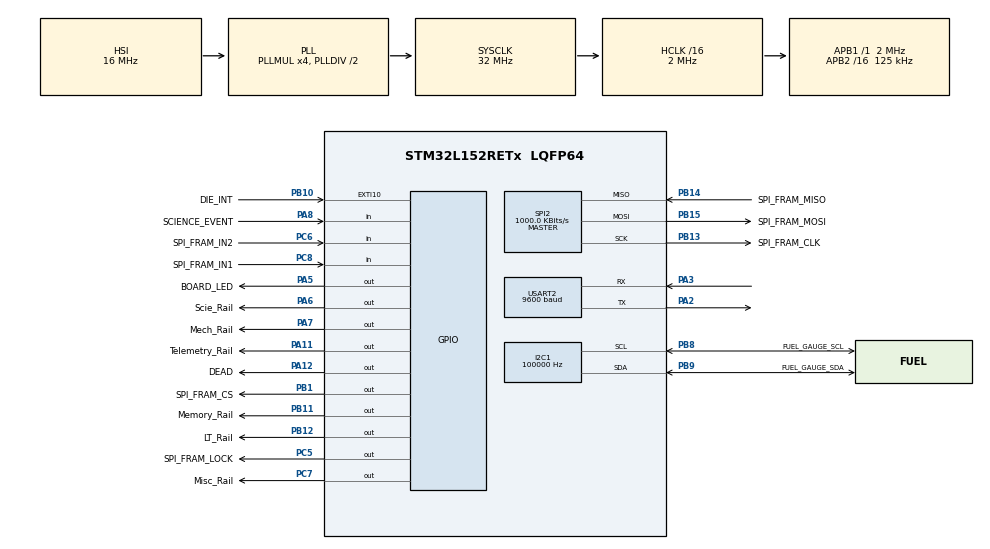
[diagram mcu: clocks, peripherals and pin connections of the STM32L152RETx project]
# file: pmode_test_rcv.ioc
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I2C1.ClockSpeed=100000
Mcu.Family=STM32L1
Mcu.Name=STM32L152RETx
Mcu.Package=LQFP64
NVIC.EXTI15_10_IRQn=true\:0\:0\:false\:false\:true\:true\:true
NVIC.PriorityGroup=NVIC_PRIORITYGROUP_4
NVIC.TIM10_IRQn=true\:0\:0\:false\:false\:true\:true\:true
PA11.GPIO_Label=Telemetry_Rail
PA11.Signal=GPIO_Output
PA12.GPIO_Label=DEAD
PA12.Signal=GPIO_Output
PA2.Mode=Asynchronous
PA2.Signal=USART2_TX
PA3.Mode=Asynchronous
PA3.Signal=USART2_RX
PA5.GPIO_Label=BOARD_LED
PA5.Signal=GPIO_Output
PA6.GPIO_Label=Scie_Rail
PA6.Signal=GPIO_Output
PA7.GPIO_Label=Mech_Rail
PA7.Signal=GPIO_Output
PA8.GPIO_Label=SCIENCE_EVENT
PA8.Signal=GPIO_Input
PB1.GPIO_Label=SPI_FRAM_CS
PB1.Signal=GPIO_Output
PB10.GPIO_Label=DIE_INT
PB10.Signal=GPXTI10
PB11.GPIO_Label=Memory_Rail
PB11.Signal=GPIO_Output
PB12.GPIO_Label=LT_Rail
PB12.Signal=GPIO_Output
PB13.GPIO_Label=SPI_FRAM_CLK
PB13.Mode=Full_Duplex_Master
PB13.Signal=SPI2_SCK
PB14.GPIO_Label=SPI_FRAM_MISO
PB14.Mode=Full_Duplex_Master
PB14.Signal=SPI2_MISO
PB15.GPIO_Label=SPI_FRAM_MOSI
PB15.Mode=Full_Duplex_Master
PB15.Signal=SPI2_MOSI
PB8.GPIO_Label=FUEL_GAUGE_SCL
PB8.Mode=I2C
PB8.Signal=I2C1_SCL
PB9.GPIO_Label=FUEL_GAUGE_SDA
PB9.Mode=I2C
PB9.Signal=I2C1_SDA
PC5.GPIO_Label=SPI_FRAM_LOCK
PC5.Signal=GPIO_Output
PC6.GPIO_Label=SPI_FRAM_IN2
PC6.Signal=GPIO_Input
PC7.GPIO_Label=Misc_Rail
PC7.Signal=GPIO_Output
PC8.GPIO_Label=SPI_FRAM_IN1
PC8.Signal=GPIO_Input
ProjectManager.HeapSize=0x200
ProjectManager.StackSize=0x400
ProjectManager.TargetToolchain=MDK-ARM V5
RCC.48MHZClocksFreq_Value=32000000
RCC.AHBCLKDivider=RCC_SYSCLK_DIV16
RCC.AHBFreq_Value=2000000
RCC.APB1Freq_Value=2000000
RCC.APB1TimFreq_Value=2000000
RCC.APB2CLKDivider=RCC_HCLK_DIV16
RCC.APB2Freq_Value=125000
RCC.APB2TimFreq_Value=250000
RCC.HCLKFreq_Value=2000000
RCC.HSE_VALUE=24000000
RCC.HSI_VALUE=16000000
RCC.LSE_VALUE=32768
RCC.MSIClockRange=RCC_MSIRANGE_6
RCC.MSI_VALUE=4194000
RCC.PLLMUL=RCC_PLL_MUL4
RCC.SYSCLKFreq_VALUE=32000000
RCC.SYSCLKSource=RCC_SYSCLKSOURCE_PLLCLK
RCC.VCOOutputFreq_Value=64000000
SPI2.BaudRatePrescaler=SPI_BAUDRATEPRESCALER_2
SPI2.CalculateBaudRate=1000.0 KBits/s
SPI2.Direction=SPI_DIRECTION_2LINES
SPI2.Mode=SPI_MODE_MASTER
SPI2.VirtualType=VM_MASTER
TIM10.ClockDivision=TIM_CLOCKDIVISION_DIV4
TIM10.Period=65535
USART2.BaudRate=9600
USART2.VirtualMode=VM_ASYNC
VP_TIM10_VS_ClockSourceINT.Mode=Internal
board=custom

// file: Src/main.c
/* USER CODE BEGIN Header */
/**
  ******************************************************************************
  * @file           : main.c
  * @brief          : Main program body
  ******************************************************************************
  ** This notice applies to any and all portions of this file
  * that are not between comment pairs USER CODE BEGIN and
  * USER CODE END. Other portions of this file, whether
  * inserted by the user or by software development tools
  * are owned by their respective copyright owners.
  *
  * COPYRIGHT(c) 2019 STMicroelectronics
  *
  * Redistribution and use in source and binary forms, with or without modification,
  * are permitted provided that the following conditions are met:
  *   1. Redistributions of source code must retain the above copyright notice,
  *      this list of conditions and the following disclaimer.
  *   2. Redistributions in binary form must reproduce the above copyright notice,
  *      this list of conditions and the following disclaimer in the documentation
  *      and/or other materials provided with the distribution.
  *   3. Neither the name of STMicroelectronics nor the names of its contributors
  *      may be used to endorse or promote products derived from this software
  *      without specific prior written permission.
  *
  * THIS SOFTWARE IS PROVIDED BY THE COPYRIGHT HOLDERS AND CONTRIBUTORS "AS IS"
  * AND ANY EXPRESS OR IMPLIED WARRANTIES, INCLUDING, BUT NOT LIMITED TO, THE
  * IMPLIED WARRANTIES OF MERCHANTABILITY AND FITNESS FOR A PARTICULAR PURPOSE ARE
  * DISCLAIMED. IN NO EVENT SHALL THE COPYRIGHT HOLDER OR CONTRIBUTORS BE LIABLE
  * FOR ANY DIRECT, INDIRECT, INCIDENTAL, SPECIAL, EXEMPLARY, OR CONSEQUENTIAL
  * DAMAGES (INCLUDING, BUT NOT LIMITED TO, PROCUREMENT OF SUBSTITUTE GOODS OR
  * SERVICES; LOSS OF USE, DATA, OR PROFITS; OR BUSINESS INTERRUPTION) HOWEVER
  * CAUSED AND ON ANY THEORY OF LIABILITY, WHETHER IN CONTRACT, STRICT LIABILITY,
  * OR TORT (INCLUDING NEGLIGENCE OR OTHERWISE) ARISING IN ANY WAY OUT OF THE USE
  * OF THIS SOFTWARE, EVEN IF ADVISED OF THE POSSIBILITY OF SUCH DAMAGE.
  *
  ******************************************************************************
  */
/* USER CODE END Header */

#include "main.h"

/* USER CODE BEGIN Includes */
#include "PowerModes.h"

/* USER CODE END Includes */

I2C_HandleTypeDef hi2c1;

SPI_HandleTypeDef hspi2;

TIM_HandleTypeDef htim10;

UART_HandleTypeDef huart2;

void SystemClock_Config(void);
static void MX_GPIO_Init(void);
static void MX_SPI2_Init(void);
static void MX_USART2_UART_Init(void);
static void MX_I2C1_Init(void);
static void MX_TIM10_Init(void);

int main(void)
{

  /* MCU Configuration--------------------------------------------------------*/

  /* Reset of all peripherals, Initializes the Flash interface and the Systick. */
  HAL_Init();

  /* Configure the system clock */
  SystemClock_Config();

  /* Initialize all configured peripherals */
  MX_GPIO_Init();
  MX_SPI2_Init();
  MX_USART2_UART_Init();
  MX_I2C1_Init();
  MX_TIM10_Init();
  /* USER CODE BEGIN 2 */
	Power_Modes_State_Machine_Init(&hi2c1, &hspi2, &huart2, &htim10);

  /* USER CODE END 2 */

  /* Infinite loop */
  /* USER CODE BEGIN WHILE */

  while (1)
  {
//		float battPercentage = Get_Voltage(&hi2c1, 0); // Currently returns a value in volts
//		snprintf(msg, 200, "\nBatt: %f \n\n", battPercentage);
//		HAL_UART_Transmit(&huart2, (uint8_t *)msg, 200, 100);
//		HAL_Delay(1000);
			Power_Modes_State_Machine_Run();

    /* USER CODE END WHILE */

  }
}

void SystemClock_Config(void)
{
  RCC_OscInitTypeDef RCC_OscInitStruct = {0};
  RCC_ClkInitTypeDef RCC_ClkInitStruct = {0};

  /** Configure the main internal regulator output voltage
  */
  __HAL_PWR_VOLTAGESCALING_CONFIG(PWR_REGULATOR_VOLTAGE_SCALE1);
  /** Initializes the CPU, AHB and APB busses clocks
  */
  RCC_OscInitStruct.OscillatorType = RCC_OSCILLATORTYPE_HSI;
  RCC_OscInitStruct.HSIState = RCC_HSI_ON;
  RCC_OscInitStruct.HSICalibrationValue = RCC_HSICALIBRATION_DEFAULT;
  RCC_OscInitStruct.PLL.PLLState = RCC_PLL_ON;
  RCC_OscInitStruct.PLL.PLLSource = RCC_PLLSOURCE_HSI;
  RCC_OscInitStruct.PLL.PLLMUL = RCC_PLL_MUL4;
  RCC_OscInitStruct.PLL.PLLDIV = RCC_PLL_DIV2;
  if (HAL_RCC_OscConfig(&RCC_OscInitStruct) != HAL_OK)
  {
    Error_Handler();
  }
  /** Initializes the CPU, AHB and APB busses clocks
  */
  RCC_ClkInitStruct.ClockType = RCC_CLOCKTYPE_HCLK|RCC_CLOCKTYPE_SYSCLK
                              |RCC_CLOCKTYPE_PCLK1|RCC_CLOCKTYPE_PCLK2;
  RCC_ClkInitStruct.SYSCLKSource = RCC_SYSCLKSOURCE_PLLCLK;
  RCC_ClkInitStruct.AHBCLKDivider = RCC_SYSCLK_DIV16;
  RCC_ClkInitStruct.APB1CLKDivider = RCC_HCLK_DIV1;
  RCC_ClkInitStruct.APB2CLKDivider = RCC_HCLK_DIV16;

  if (HAL_RCC_ClockConfig(&RCC_ClkInitStruct, FLASH_LATENCY_0) != HAL_OK)
  {
    Error_Handler();
  }
}

static void MX_I2C1_Init(void)
{

  hi2c1.Instance = I2C1;
  hi2c1.Init.ClockSpeed = 100000;
  hi2c1.Init.DutyCycle = I2C_DUTYCYCLE_2;
  hi2c1.Init.OwnAddress1 = 0;
  hi2c1.Init.AddressingMode = I2C_ADDRESSINGMODE_7BIT;
  hi2c1.Init.DualAddressMode = I2C_DUALADDRESS_DISABLE;
  hi2c1.Init.OwnAddress2 = 0;
  hi2c1.Init.GeneralCallMode = I2C_GENERALCALL_DISABLE;
  hi2c1.Init.NoStretchMode = I2C_NOSTRETCH_DISABLE;
  if (HAL_I2C_Init(&hi2c1) != HAL_OK)
  {
    Error_Handler();
  }

}

static void MX_SPI2_Init(void)
{

  /* SPI2 parameter configuration*/
  hspi2.Instance = SPI2;
  hspi2.Init.Mode = SPI_MODE_MASTER;
  hspi2.Init.Direction = SPI_DIRECTION_2LINES;
  hspi2.Init.DataSize = SPI_DATASIZE_8BIT;
  hspi2.Init.CLKPolarity = SPI_POLARITY_LOW;
  hspi2.Init.CLKPhase = SPI_PHASE_1EDGE;
  hspi2.Init.NSS = SPI_NSS_SOFT;
  hspi2.Init.BaudRatePrescaler = SPI_BAUDRATEPRESCALER_2;
  hspi2.Init.FirstBit = SPI_FIRSTBIT_MSB;
  hspi2.Init.TIMode = SPI_TIMODE_DISABLE;
  hspi2.Init.CRCCalculation = SPI_CRCCALCULATION_DISABLE;
  hspi2.Init.CRCPolynomial = 10;
  if (HAL_SPI_Init(&hspi2) != HAL_OK)
  {
    Error_Handler();
  }

}

static void MX_TIM10_Init(void)
{

  TIM_ClockConfigTypeDef sClockSourceConfig = {0};

  htim10.Instance = TIM10;
  htim10.Init.Prescaler = 0;
  htim10.Init.CounterMode = TIM_COUNTERMODE_UP;
  htim10.Init.Period = 65535;
  htim10.Init.ClockDivision = TIM_CLOCKDIVISION_DIV4;
  htim10.Init.AutoReloadPreload = TIM_AUTORELOAD_PRELOAD_DISABLE;
  if (HAL_TIM_Base_Init(&htim10) != HAL_OK)
  {
    Error_Handler();
  }
  sClockSourceConfig.ClockSource = TIM_CLOCKSOURCE_INTERNAL;
  if (HAL_TIM_ConfigClockSource(&htim10, &sClockSourceConfig) != HAL_OK)
  {
    Error_Handler();
  }

}

static void MX_USART2_UART_Init(void)
{

  huart2.Instance = USART2;
  huart2.Init.BaudRate = 9600;
  huart2.Init.WordLength = UART_WORDLENGTH_8B;
  huart2.Init.StopBits = UART_STOPBITS_1;
  huart2.Init.Parity = UART_PARITY_NONE;
  huart2.Init.Mode = UART_MODE_TX_RX;
  huart2.Init.HwFlowCtl = UART_HWCONTROL_NONE;
  huart2.Init.OverSampling = UART_OVERSAMPLING_16;
  if (HAL_UART_Init(&huart2) != HAL_OK)
  {
    Error_Handler();
  }

}

static void MX_GPIO_Init(void)
{
  GPIO_InitTypeDef GPIO_InitStruct = {0};

  /* GPIO Ports Clock Enable */
  __HAL_RCC_GPIOA_CLK_ENABLE();
  __HAL_RCC_GPIOC_CLK_ENABLE();
  __HAL_RCC_GPIOB_CLK_ENABLE();

  /*Configure GPIO pin Output Level */
  HAL_GPIO_WritePin(GPIOA, BOARD_LED_Pin|Scie_Rail_Pin|Mech_Rail_Pin|Telemetry_Rail_Pin
                          |DEAD_Pin, GPIO_PIN_RESET);

  /*Configure GPIO pin Output Level */
  HAL_GPIO_WritePin(GPIOC, SPI_FRAM_LOCK_Pin|Misc_Rail_Pin, GPIO_PIN_RESET);

  /*Configure GPIO pin Output Level */
  HAL_GPIO_WritePin(GPIOB, SPI_FRAM_CS_Pin|Memory_Rail_Pin|LT_Rail_Pin, GPIO_PIN_RESET);

  /*Configure GPIO pins : BOARD_LED_Pin Scie_Rail_Pin Mech_Rail_Pin Telemetry_Rail_Pin
                           DEAD_Pin */
  GPIO_InitStruct.Pin = BOARD_LED_Pin|Scie_Rail_Pin|Mech_Rail_Pin|Telemetry_Rail_Pin
                          |DEAD_Pin;
  GPIO_InitStruct.Mode = GPIO_MODE_OUTPUT_PP;
  GPIO_InitStruct.Pull = GPIO_NOPULL;
  GPIO_InitStruct.Speed = GPIO_SPEED_FREQ_LOW;
  HAL_GPIO_Init(GPIOA, &GPIO_InitStruct);

  /*Configure GPIO pins : SPI_FRAM_LOCK_Pin Misc_Rail_Pin */
  GPIO_InitStruct.Pin = SPI_FRAM_LOCK_Pin|Misc_Rail_Pin;
  GPIO_InitStruct.Mode = GPIO_MODE_OUTPUT_PP;
  GPIO_InitStruct.Pull = GPIO_NOPULL;
  GPIO_InitStruct.Speed = GPIO_SPEED_FREQ_LOW;
  HAL_GPIO_Init(GPIOC, &GPIO_InitStruct);

  /*Configure GPIO pins : SPI_FRAM_CS_Pin Memory_Rail_Pin LT_Rail_Pin */
  GPIO_InitStruct.Pin = SPI_FRAM_CS_Pin|Memory_Rail_Pin|LT_Rail_Pin;
  GPIO_InitStruct.Mode = GPIO_MODE_OUTPUT_PP;
  GPIO_InitStruct.Pull = GPIO_NOPULL;
  GPIO_InitStruct.Speed = GPIO_SPEED_FREQ_LOW;
  HAL_GPIO_Init(GPIOB, &GPIO_InitStruct);

  /*Configure GPIO pin : DIE_INT_Pin */
  GPIO_InitStruct.Pin = DIE_INT_Pin;
  GPIO_InitStruct.Mode = GPIO_MODE_IT_RISING;
  GPIO_InitStruct.Pull = GPIO_NOPULL;
  HAL_GPIO_Init(DIE_INT_GPIO_Port, &GPIO_InitStruct);

  /*Configure GPIO pins : SPI_FRAM_IN2_Pin SPI_FRAM_IN1_Pin */
  GPIO_InitStruct.Pin = SPI_FRAM_IN2_Pin|SPI_FRAM_IN1_Pin;
  GPIO_InitStruct.Mode = GPIO_MODE_INPUT;
  GPIO_InitStruct.Pull = GPIO_NOPULL;
  HAL_GPIO_Init(GPIOC, &GPIO_InitStruct);

  /*Configure GPIO pin : SCIENCE_EVENT_Pin */
  GPIO_InitStruct.Pin = SCIENCE_EVENT_Pin;
  GPIO_InitStruct.Mode = GPIO_MODE_INPUT;
  GPIO_InitStruct.Pull = GPIO_NOPULL;
  HAL_GPIO_Init(SCIENCE_EVENT_GPIO_Port, &GPIO_InitStruct);

  /* EXTI interrupt init*/
  HAL_NVIC_SetPriority(EXTI15_10_IRQn, 0, 0);
  HAL_NVIC_EnableIRQ(EXTI15_10_IRQn);

}

void Error_Handler(void)
{
}

/************************ (C) COPYRIGHT STMicroelectronics *****END OF FILE****/
